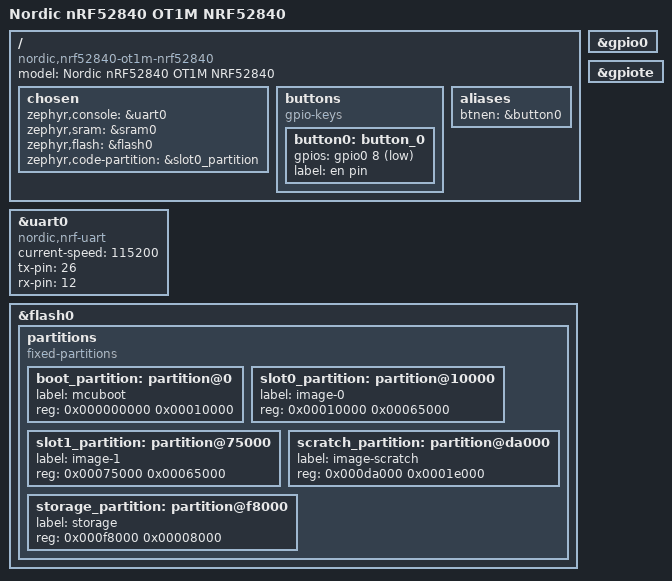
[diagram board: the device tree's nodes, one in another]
/*
 *
 * SPDX-License-Identifier: Apache-2.0
 */

/dts-v1/;
#include <nordic/nrf52840_qiaa.dtsi>

/ {
	model = "Nordic nRF52840 OT1M NRF52840";
	compatible = "nordic,nrf52840-ot1m-nrf52840";

	chosen {
		zephyr,console = &uart0;
		zephyr,sram = &sram0;
		zephyr,flash = &flash0;
		zephyr,code-partition = &slot0_partition;
	};

	buttons {
		compatible = "gpio-keys";
		button0: button_0 {
			gpios = <&gpio0 8 (GPIO_PULL_UP | GPIO_ACTIVE_LOW)>;
			label = "en pin";
		};
	};

	/* These aliases are provided for compatibility with samples */
	aliases {
		btnen = &button0;
	};
};

&gpio0 {
	status = "okay";
};

&gpiote {
	status = "okay";
};

&uart0 {
	compatible = "nordic,nrf-uart";
	status = "okay";
	current-speed = <115200>;
	tx-pin = <26>;
	rx-pin = <12>;
};

&flash0 {
	/*
	 * For more information, see:
	 * http://docs.zephyrproject.org/latest/guides/dts/index.html#flash-partitions
	 */
	partitions {
		compatible = "fixed-partitions";
		#address-cells = <1>;
		#size-cells = <1>;

		boot_partition: partition@0 {
			label = "mcuboot";
			reg = <0x000000000 0x00010000>;
		};
		slot0_partition: partition@10000 {
			label = "image-0";
			reg = <0x00010000 0x00065000>;
		};
		slot1_partition: partition@75000 {
			label = "image-1";
			reg = <0x00075000 0x00065000>;
		};
		scratch_partition: partition@da000 {
			label = "image-scratch";
			reg = <0x000da000 0x0001e000>;
		};

		/*
		 * The flash starting at 0x000f8000 and ending at
		 * 0x000fffff is reserved for use by the application.
		 */

		/*
		 * Storage partition will be used by FCB/LittleFS/NVS
		 * if enabled.
		 */
		storage_partition: partition@f8000 {
			label = "storage";
			reg = <0x000f8000 0x00008000>;
		};
	};
};
